AUTOSAR XML (schema 4-2-2)
package /AUTOLIV/SoftwareComponents/HWA
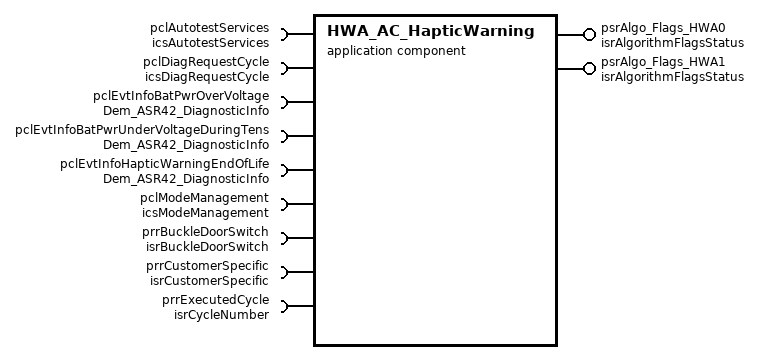
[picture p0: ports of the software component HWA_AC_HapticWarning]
  application sw component type HWA_AC_HapticWarning: category=SWC
    9 x require port:
      pclAutotestServices: required-com-specs=[GetTestResult, GetLastCriticalAutotestID], required-interface=icsAutotestServices
      pclDiagRequestCycle: required-com-specs=[GetDiagRequestCycle, ClearDiagRequestCycle], required-interface=icsDiagRequestCycle
      pclEvtInfoBatPwrOverVoltage: required-interface=Dem_ASR42_DiagnosticInfo
        required-com-specs:
          GetEventStatus
          GetEventFailed
          GetEventTested
          GetDTCOfEvent
          GetFaultDetectionCounter
          GetEventFreezeFrameData
          GetEventExtendedDataRecord
      pclEvtInfoBatPwrUnderVoltageDuringTens: required-interface=Dem_ASR42_DiagnosticInfo
        required-com-specs:
          GetEventStatus
          GetEventFailed
          GetEventTested
          GetDTCOfEvent
          GetFaultDetectionCounter
          GetEventFreezeFrameData
          GetEventExtendedDataRecord
      pclEvtInfoHapticWarningEndOfLife: required-interface=Dem_ASR42_DiagnosticInfo
        required-com-specs:
          GetEventStatus
          GetEventFailed
          GetEventTested
          GetDTCOfEvent
          GetFaultDetectionCounter
          GetEventFreezeFrameData
          GetEventExtendedDataRecord
      pclModeManagement: client-com-spec=CheckModeStatus, required-interface=icsModeManagement
      prrBuckleDoorSwitch: required-interface=isrBuckleDoorSwitch
        required-com-specs:
          data-element=u8BuckleSwitch, uses-end-to-end-protection=0, init-value=constant-reference=APPLINIT_KU8_BUCKLE_SWITCH_STATUS_NOT_DEFINED
          data-element=u8DoorSwitch, uses-end-to-end-protection=0, init-value=constant-reference=APPLINIT_KU8_DOOR_SWITCH_STATUS_NOT_DEFINED
      prrCustomerSpecific: required-interface=isrCustomerSpecific
        required-com-specs:
          data-element=b8IsCarCrashDetected, uses-end-to-end-protection=0, init-value=constant-reference=APPLINIT_KB8_CAR_CRASH_DETECTED_FALSE
          data-element=b8IsCarCrankingActive, uses-end-to-end-protection=0, init-value=constant-reference=APPLINIT_KB8_CAR_CRANKING_ACTIVE_TRUE
          data-element=u8BeltSlackStatus, uses-end-to-end-protection=0, init-value=constant-reference=APPLINIT_KU8_BELT_SLACK_STATUS_NOT_DEFINED
          data-element=u8PreCrashRequest, uses-end-to-end-protection=0, init-value=constant-reference=APPLINIT_KU8_PRE_CRASH_REQUEST_NO_REQUEST
          data-element=b8PreCrashRequestEnable, uses-end-to-end-protection=0, init-value=constant-reference=APPLINIT_KB8_BOOLEAN_FALSE
          data-element=u8HapticRequest, uses-end-to-end-protection=0, init-value=constant-reference=APPLINIT_KU8_HAPTIC_REQUEST_NO
      prrExecutedCycle: nonqueued-receiver-com-spec{data-element=u8CycleNumber, uses-end-to-end-protection=0, init-value=constant-reference=APPLINIT_KU8_CYCLE_NUMBER_NONE}, required-interface=isrCycleNumber
    provide port psrAlgo_Flags_HWA0: provided-interface=isrAlgorithmFlagsStatus
      provided-com-specs:
        data-element=b8TriggerFlag, uses-end-to-end-protection=0, init-value=constant-reference=APPLINIT_KB8_ALGO_FLAG_FALSE
        data-element=b8InterruptFlag, uses-end-to-end-protection=0, init-value=constant-reference=APPLINIT_KB8_ALGO_FLAG_FALSE
        data-element=b8PreActivationFlag, uses-end-to-end-protection=0, init-value=constant-reference=APPLINIT_KB8_ALGO_FLAG_FALSE
        data-element=b8PreConditionsFlag, uses-end-to-end-protection=0, init-value=constant-reference=APPLINIT_KB8_ALGO_FLAG_FALSE
        data-element=u8TriggeringSource, uses-end-to-end-protection=0, init-value=constant-reference=APPLINIT_KU8_TRIGGERING_SOURCE_NO
    provide port psrAlgo_Flags_HWA1: provided-interface=isrAlgorithmFlagsStatus
      provided-com-specs:
        data-element=b8TriggerFlag, uses-end-to-end-protection=0, init-value=constant-reference=APPLINIT_KB8_ALGO_FLAG_FALSE
        data-element=b8InterruptFlag, uses-end-to-end-protection=0, init-value=constant-reference=APPLINIT_KB8_ALGO_FLAG_FALSE
        data-element=b8PreActivationFlag, uses-end-to-end-protection=0, init-value=constant-reference=APPLINIT_KB8_ALGO_FLAG_FALSE
        data-element=b8PreConditionsFlag, uses-end-to-end-protection=0, init-value=constant-reference=APPLINIT_KB8_ALGO_FLAG_FALSE
        data-element=u8TriggeringSource, uses-end-to-end-protection=0, init-value=constant-reference=APPLINIT_KU8_TRIGGERING_SOURCE_NO
